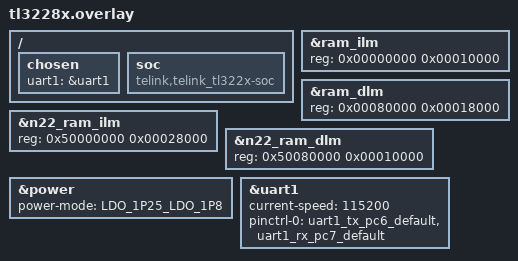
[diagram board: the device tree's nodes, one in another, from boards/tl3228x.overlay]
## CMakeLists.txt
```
# SPDX-License-Identifier: Apache-2.0

cmake_minimum_required(VERSION 3.20.0)
find_package(Zephyr REQUIRED HINTS $ENV{ZEPHYR_BASE})
project(dtm_hci)

target_sources(app PRIVATE
  src/hci_uart_transport.c
  src/main.c
)
```

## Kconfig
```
mainmenu "Telink DTM HCI Bridge Sample"

config DTM_HCI_BAUDRATE
	int "HCI UART baudrate"
	default 115200
	help
	  Baudrate for the HCI UART transport used to communicate
	  with the host (upper tester).

module = DTM_HCI_UART_TRANSPORT
module-str = "DTM HCI UART transport"
source "subsys/logging/Kconfig.template.log_config"

source "Kconfig.zephyr"
```

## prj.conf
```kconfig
# IO - Enable console on UART0 for debug logs
CONFIG_CONSOLE=y
CONFIG_UART_CONSOLE=y
CONFIG_UART_USE_RUNTIME_CONFIGURE=y

# Enable N22 core support (shared memory + mailbox communication)
# This triggers soc_tlx_mcc_init() which calls mcc_d25f_service_init()
# to set up mailbox IRQ and shared memory FIFOs during SYS_INIT.
CONFIG_TELINK_TL322X_ENABLE_N22=y

# BT TLX driver - required to compile MCC shared memory sources
# (service_d25f.c, mcc.c, etc. are built under CONFIG_BT_TLX).
# We do NOT call bt_enable_raw(), so no controller thread starts.
CONFIG_BT=y
CONFIG_BT_TLX=y

# Buffer sizes for HCI packets (up to 260 bytes for ACL)
CONFIG_NET_BUF=y
CONFIG_BT_BUF_CMD_TX_SIZE=255
CONFIG_BT_BUF_EVT_RX_SIZE=255

# Logging
CONFIG_LOG=y
CONFIG_LOG_PRINTK=y

# Enable debug logging for HCI UART transport
CONFIG_DTM_HCI_UART_TRANSPORT_LOG_LEVEL_DBG=y
```

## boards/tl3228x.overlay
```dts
/*
 * Copyright (c) 2026 Telink Semiconductor
 *
 * SPDX-License-Identifier: Apache-2.0
 */

#include <zephyr/dt-bindings/pinctrl/tl322x-pinctrl.h>

/ {
	chosen {
		/* Use UART1 for HCI transport (DT_CHOSEN(uart1) in sample) */
		uart1 = &uart1;
	};

	soc {
		compatible = "telink,telink_tl322x-soc";
	};
};

/* Memory layout override (values match board defaults, kept for clarity) */
&ram_ilm {
	reg = <0x00000000 0x00010000>;
};

&ram_dlm {
	reg = <0x00080000 0x00018000>;
};

&n22_ram_ilm {
	reg = <0x50000000 0x00028000>;
};

&n22_ram_dlm {
	reg = <0x50080000 0x00010000>;
};


&power {
	power-mode = "LDO_1P25_LDO_1P8";
};

/* Additional pinctrl states: UART0 remapped to PC0/PC1, UART1 remapped to PB0/PB1 */


&uart1 {
	status = "okay";
	current-speed = <115200>;
	pinctrl-0 = <&uart1_tx_pc6_default &uart1_rx_pc7_default>;
	pinctrl-names = "default";
};
```

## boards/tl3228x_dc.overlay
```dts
/*
 * Copyright (c) 2026 Telink Semiconductor
 *
 * SPDX-License-Identifier: Apache-2.0
 */

#include <zephyr/dt-bindings/pinctrl/tl322x-pinctrl.h>

/ {
	chosen {
		/* UART0: console/debug log, UART1: HCI transport */
		uart1 = &uart1;
	};
};

&power {
	power-mode = "LDO_1P25_LDO_1P8";
};

&pinctrl {
	uart1_tx_pd6_default: uart1_tx_pd6_default {
		pinmux = <TLX_PINMUX_SET(TLX_PORT_D, TLX_PIN_6, TL322X_FUNC_UART1_TX)>;
	};
	uart1_rx_pd7_default: uart1_rx_pd7_default {
		pinmux = <TLX_PINMUX_SET(TLX_PORT_D, TLX_PIN_7, TL322X_FUNC_UART1_RTX_IO)>;
	};
};

/* UART1 on PC6(TX)/PC7(RX) for HCI transport */
&uart1 {
	status = "okay";
	current-speed = <115200>;
	pinctrl-0 = <&uart1_tx_pd6_default &uart1_rx_pd7_default>;
	pinctrl-names = "default";
};
```

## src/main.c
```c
/*
 * Copyright (c) 2026 Nordic Semiconductor ASA
 *
 * SPDX-License-Identifier: LicenseRef-Nordic-5-Clause
 *
 * DTM HCI Bridge Sample
 *
 * This sample runs on the D25F core of TL322X. It acts as an HCI transport
 * bridge between the host (connected via UART) and the N22 core (BLE controller):
 *
 *   Host UART  --HCI-->  D25F  --shared memory-->  N22 (BLE controller)
 *   Host UART  <--HCI--  D25F  <--shared memory--  N22 (BLE controller)
 *
 * D25F receives HCI H4 packets from UART and forwards them to N22 via
 * shared memory. HCI events/responses from N22 are received via shared
 * memory and forwarded back to the host via UART.
 */

#include <zephyr/kernel.h>
#include <zephyr/logging/log.h>

#include "hci_uart_transport.h"
#include "service_d25f.h"
#include "mcc.h"

LOG_MODULE_REGISTER(main, CONFIG_LOG_DEFAULT_LEVEL);

/* Timeout for waiting for N22 HCI response */
#define HCI_RESPONSE_TIMEOUT_MS 5000

/* Poll interval for mcc_d25f_loop() while waiting for response */
#define SHM_POLL_INTERVAL_MS 1

/* Maximum HCI packet size including H4 type byte */
#define HCI_PKT_BUF_SIZE HCI_UART_MAX_PKT_SIZE

/* Semaphore signaled by the shared memory callback when an HCI packet
 * arrives from the N22 core.
 */
static K_SEM_DEFINE(shm_hci_sem, 0, 1);

/* Buffer for HCI packets received from N22 via shared memory */
static uint8_t shm_hci_buf[HCI_PKT_BUF_SIZE];
static volatile size_t shm_hci_len;

/* Shared memory receive callback for TLK_SHM_MSG_HCI messages from N22.
 * Called by mcc_d25f_loop() when the controller thread pops a message
 * from the N22-to-D25F shared memory FIFO.
 *
 * The data format is: [H4 type (1 byte)] [HCI payload ...]
 * This matches the format used by mcc_d25f_hci_send_msg().
 */
static void dtm_shm_hci_recv_cb(uint8_t *pData, uint16_t len)
{
	if (len > HCI_PKT_BUF_SIZE) {
		LOG_ERR("HCI packet too large from N22: %u bytes", len);
		return;
	}

	memcpy(shm_hci_buf, pData, len);
	shm_hci_len = len;
	k_sem_give(&shm_hci_sem);
}

int main(void)
{
	printk("Starting DTM HCI bridge sample\n");

	int err;

	err = hci_uart_init();
	if (err) {
		printk("HCI UART init failed: %d\n", err);
		return err;
	}

	/* Register shared memory callback for TLK_SHM_MSG_HCI messages.
	 * N22 (BLE controller) sends HCI events and command responses
	 * via this message type.
	 */
	mcc_d25f_register_shm_recv_cb(TLK_SHM_MSG_HCI, dtm_shm_hci_recv_cb);

	for (;;) {
		/* Receive HCI packet from host via UART */
		uint8_t hci_pkt[HCI_PKT_BUF_SIZE];
		size_t hci_len = 0;

		printk("Waiting for HCI packet from UART...\n");

		err = hci_uart_read(hci_pkt, &hci_len);
		if (err) {
			printk("HCI UART read error: %d\n", err);
			continue;
		}

		printk("Received HCI packet: type=0x%02X, len=%zu\n",
		       hci_pkt[0], hci_len);

		/* Forward HCI packet to N22 via shared memory.
		 * mcc_d25f_hci_send_msg expects [H4 type][HCI payload] format.
		 */
		shm_fifo_status_e shm_ret = mcc_d25f_hci_send_msg(hci_pkt, hci_len);

		if (shm_ret != SHM_FIFO_SUCCESS) {
			printk("Failed to send HCI to N22: %d\n", shm_ret);
			continue;
		}

		/* Poll for response from N22.
		 * mcc_d25f_loop() pops messages from the N22-to-D25F FIFO
		 * and dispatches them to registered callbacks (including ours).
		 */
		bool got_response = false;
		int64_t deadline = k_uptime_get() + HCI_RESPONSE_TIMEOUT_MS;

		while (k_uptime_get() < deadline) {
			mcc_d25f_loop();

			/* Check if our callback was invoked */
			while (k_sem_take(&shm_hci_sem, K_NO_WAIT) == 0) {
				got_response = true;

				printk("Received HCI response: type=0x%02X, len=%zu\n",
				       shm_hci_buf[0], shm_hci_len);

				/* Forward HCI response to host via UART */
				hci_uart_write(shm_hci_buf, shm_hci_len);
			}

			if (got_response) {
				break;
			}

			k_sleep(K_MSEC(SHM_POLL_INTERVAL_MS));
		}

		if (!got_response) {
			printk("Timeout waiting for N22 HCI response\n");
		}
	}
}
```

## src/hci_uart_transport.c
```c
/*
 * Copyright (c) 2026 Nordic Semiconductor ASA
 *
 * SPDX-License-Identifier: LicenseRef-Nordic-5-Clause
 */

#include <errno.h>
#include <zephyr/drivers/uart.h>
#include <zephyr/logging/log.h>
#include <zephyr/kernel.h>

#include "hci_uart_transport.h"

LOG_MODULE_REGISTER(hci_uart, CONFIG_DTM_HCI_UART_TRANSPORT_LOG_LEVEL);

/* HCI H4 packet type indicators */
#define HCI_H4_CMD  0x01
#define HCI_H4_ACL  0x02
#define HCI_H4_SCO  0x03
#define HCI_H4_EVT  0x04
#define HCI_H4_ISO  0x05

/* HCI header sizes (not including H4 type byte) */
#define HCI_CMD_HDR_SIZE  3  /* opcode(2) + param_len(1) */
#define HCI_ACL_HDR_SIZE  4  /* handle(2) + data_len(2) */
#define HCI_SCO_HDR_SIZE  3  /* handle(2) + data_len(1) */
#define HCI_EVT_HDR_SIZE  2  /* event_code(1) + param_len(1) */
#define HCI_ISO_HDR_SIZE  4  /* handle(2) + data_len(2) */

#define DTM_UART DT_CHOSEN(uart1)

#ifndef CONFIG_DTM_HCI_BAUDRATE
#define CONFIG_DTM_HCI_BAUDRATE 115200
#endif

/* Poll cycle in microseconds based on baudrate (10 bits per byte) */
#define UART_POLL_CYCLE_US ((uint32_t)(10U * 1000000U / CONFIG_DTM_HCI_BAUDRATE))

static const struct device *hci_uart_dev = DEVICE_DT_GET_OR_NULL(DTM_UART);

/**
 * @brief Get the expected payload length from an HCI header.
 *
 * @param h4_type  HCI H4 packet type.
 * @param header   Pointer to the HCI header bytes.
 * @param hdr_len  Length of the header that has been read.
 * @param[out] payload_len  Expected payload length beyond the header.
 *
 * @return 0 on success, -EINVAL if unknown H4 type or insufficient header.
 */
static int hci_get_payload_len(uint8_t h4_type, const uint8_t *header,
			       size_t hdr_len, size_t *payload_len)
{
	switch (h4_type) {
	case HCI_H4_CMD:
		if (hdr_len < HCI_CMD_HDR_SIZE) {
			return -EINVAL;
		}
		*payload_len = header[2]; /* param_len */
		return 0;

	case HCI_H4_ACL:
		if (hdr_len < HCI_ACL_HDR_SIZE) {
			return -EINVAL;
		}
		*payload_len = header[2] | ((uint16_t)header[3] << 8);
		return 0;

	case HCI_H4_SCO:
		if (hdr_len < HCI_SCO_HDR_SIZE) {
			return -EINVAL;
		}
		*payload_len = header[2];
		return 0;

	case HCI_H4_EVT:
		if (hdr_len < HCI_EVT_HDR_SIZE) {
			return -EINVAL;
		}
		*payload_len = header[1]; /* param_len */
		return 0;

	case HCI_H4_ISO:
		if (hdr_len < HCI_ISO_HDR_SIZE) {
			return -EINVAL;
		}
		/* ISO: last 2 bytes of header are data_len (little-endian) */
		*payload_len = header[hdr_len - 2] |
			       ((uint16_t)header[hdr_len - 1] << 8);
		return 0;

	default:
		return -EINVAL;
	}
}

/**
 * @brief Get the HCI header size for a given H4 packet type.
 */
static size_t hci_hdr_size(uint8_t h4_type)
{
	switch (h4_type) {
	case HCI_H4_CMD: return HCI_CMD_HDR_SIZE;
	case HCI_H4_ACL: return HCI_ACL_HDR_SIZE;
	case HCI_H4_SCO: return HCI_SCO_HDR_SIZE;
	case HCI_H4_EVT: return HCI_EVT_HDR_SIZE;
	case HCI_H4_ISO: return HCI_ISO_HDR_SIZE;
	default:         return 0;
	}
}

int hci_uart_init(void)
{
	if (!device_is_ready(hci_uart_dev)) {
		LOG_ERR("UART device not ready");
		return -EIO;
	}

	struct uart_config cfg;
	int ret = uart_config_get(hci_uart_dev, &cfg);

	if (ret != 0) {
		return ret;
	}

	cfg.baudrate = CONFIG_DTM_HCI_BAUDRATE;
	ret = uart_configure(hci_uart_dev, &cfg);
	if (ret != 0) {
		return ret;
	}

	LOG_INF("HCI UART initialized at %d baud", CONFIG_DTM_HCI_BAUDRATE);
	return 0;
}

int hci_uart_read(uint8_t *buf, size_t *len)
{
	if (buf == NULL || len == NULL) {
		return -EINVAL;
	}

	uint8_t rx_byte;
	int err;
	size_t idx = 0;
	size_t expected_total = 0; /* 0 means waiting for H4 type byte */
	size_t hdr_len;
	uint8_t h4_type;

	for (;;) {
		k_sleep(K_USEC(UART_POLL_CYCLE_US));

		err = uart_poll_in(hci_uart_dev, &rx_byte);
		if (err) {
			if (err != -1) {
				LOG_ERR("UART polling error: %d", err);
			}
			continue;
		}

		if (idx == 0) {
			/* First byte: H4 packet type */
			h4_type = rx_byte;
			hdr_len = hci_hdr_size(h4_type);
			if (hdr_len == 0) {
				LOG_ERR("Unknown H4 packet type 0x%02X, discarding", h4_type);
				/* Reset and wait for next valid type byte */
				continue;
			}
			buf[idx++] = rx_byte;
			/* We still need the header to determine total length */
			expected_total = 0;
			continue;
		}

		buf[idx++] = rx_byte;

		/* After reading the H4 type, we need header + payload.
		 * Once we have the full header, compute the total expected size.
		 */
		if (expected_total == 0 && idx >= 1 + hdr_len) {
			size_t payload_len;

			err = hci_get_payload_len(h4_type, buf + 1, hdr_len, &payload_len);
			if (err) {
				LOG_ERR("Failed to get payload length for type 0x%02X", h4_type);
				idx = 0;
				continue;
			}

			expected_total = 1 + hdr_len + payload_len;

			if (expected_total > HCI_UART_MAX_PKT_SIZE) {
				LOG_ERR("Packet too large: %zu bytes", expected_total);
				idx = 0;
				expected_total = 0;
				continue;
			}
		}

		/* Check if we have received the complete packet */
		if (expected_total > 0 && idx >= expected_total) {
			*len = idx;
			LOG_DBG("Received HCI packet: type=0x%02X, len=%zu", h4_type, idx);
			return 0;
		}
	}
}

void hci_uart_write(const uint8_t *buf, size_t len)
{
	if (buf == NULL || len == 0) {
		return;
	}

	LOG_DBG("Sending HCI packet: type=0x%02X, len=%zu", buf[0], len);

	for (size_t i = 0; i < len; i++) {
		uart_poll_out(hci_uart_dev, buf[i]);
	}
}
```

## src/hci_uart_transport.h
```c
/*
 * Copyright (c) 2026 Nordic Semiconductor ASA
 *
 * SPDX-License-Identifier: LicenseRef-Nordic-5-Clause
 */

#ifndef HCI_UART_TRANSPORT_H_
#define HCI_UART_TRANSPORT_H_

#include <stdint.h>
#include <stddef.h>

#ifdef __cplusplus
extern "C" {
#endif

/**
 * @file
 * @defgroup dtm_hci_uart_transport DTM HCI UART Transport
 * @{
 * @brief HCI H4 UART transport layer for the DTM HCI bridge sample.
 *
 * This module handles reading and writing complete HCI H4 packets
 * over the UART interface. Each packet on the wire has the format:
 *   [H4 packet type (1 byte)] [HCI payload ...]
 *
 * H4 packet types:
 *   0x01 = HCI Command
 *   0x02 = ACL Data
 *   0x03 = SCO Data
 *   0x04 = HCI Event
 *   0x05 = ISO Data
 */

/** Maximum size of a single HCI H4 packet (type byte + max payload). */
#define HCI_UART_MAX_PKT_SIZE 260

/**
 * @brief Initialize the HCI UART transport.
 *
 * Configures the UART with the baudrate specified by
 * CONFIG_DTM_HCI_BAUDRATE (default 115200).
 *
 * @return 0 on success, negative error code on failure.
 */
int hci_uart_init(void);

/**
 * @brief Read a complete HCI H4 packet from UART (blocking).
 *
 * This function blocks until a complete HCI packet is received.
 * The output buffer contains the H4 type byte followed by the
 * HCI payload.
 *
 * @param[out] buf   Buffer to store the received packet.
 * @param[out] len   Actual length of the received packet (including H4 byte).
 *
 * @return 0 on success, negative error code on failure.
 */
int hci_uart_read(uint8_t *buf, size_t *len);

/**
 * @brief Write an HCI H4 packet to UART.
 *
 * The buffer must start with the H4 type byte followed by the HCI payload.
 *
 * @param[in] buf  Buffer containing the HCI H4 packet to send.
 * @param[in] len  Length of the packet (including H4 byte).
 */
void hci_uart_write(const uint8_t *buf, size_t len);

#ifdef __cplusplus
}
#endif

/**
 * @}
 */

#endif /* HCI_UART_TRANSPORT_H_ */
```
